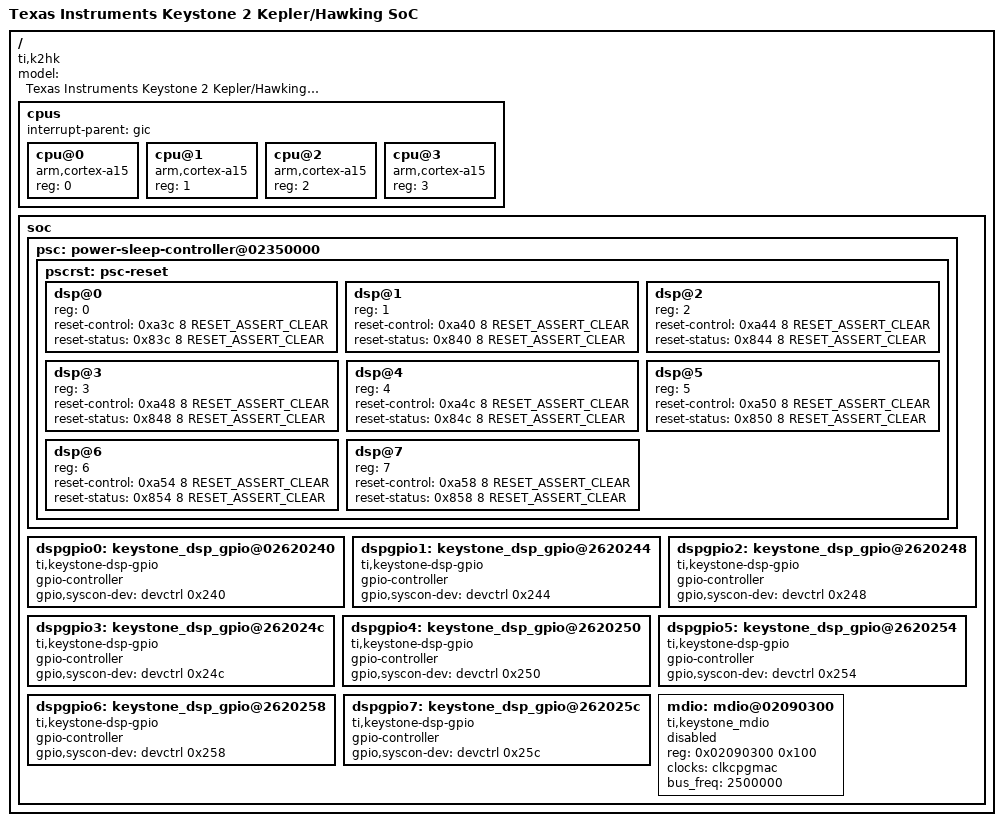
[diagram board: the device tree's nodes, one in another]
/*
 * Copyright 2013-2014 Texas Instruments, Inc.
 *
 * Keystone 2 Kepler/Hawking soc specific device tree
 *
 * This program is free software; you can redistribute it and/or modify
 * it under the terms of the GNU General Public License version 2 as
 * published by the Free Software Foundation.
 */

/ {
	compatible = "ti,k2hk", "ti,keystone";
	model = "Texas Instruments Keystone 2 Kepler/Hawking SoC";

	cpus {
		#address-cells = <1>;
		#size-cells = <0>;

		interrupt-parent = <&gic>;

		cpu@0 {
			compatible = "arm,cortex-a15";
			device_type = "cpu";
			reg = <0>;
		};

		cpu@1 {
			compatible = "arm,cortex-a15";
			device_type = "cpu";
			reg = <1>;
		};

		cpu@2 {
			compatible = "arm,cortex-a15";
			device_type = "cpu";
			reg = <2>;
		};

		cpu@3 {
			compatible = "arm,cortex-a15";
			device_type = "cpu";
			reg = <3>;
		};
	};

	soc {
		/include/ "keystone-k2hk-clocks.dtsi"

		psc: power-sleep-controller@02350000 {
			pscrst: psc-reset {
				dsp@0 {
					reg = <0>;
					reset-control = <0xa3c 8 RESET_ASSERT_CLEAR>;
					reset-status = <0x83c 8 RESET_ASSERT_CLEAR>;
				};

				dsp@1 {
					reg = <1>;
					reset-control = <0xa40 8 RESET_ASSERT_CLEAR>;
					reset-status = <0x840 8 RESET_ASSERT_CLEAR>;
				};

				dsp@2 {
					reg = <2>;
					reset-control = <0xa44 8 RESET_ASSERT_CLEAR>;
					reset-status = <0x844 8 RESET_ASSERT_CLEAR>;
				};

				dsp@3 {
					reg = <3>;
					reset-control = <0xa48 8 RESET_ASSERT_CLEAR>;
					reset-status = <0x848 8 RESET_ASSERT_CLEAR>;
				};

				dsp@4 {
					reg = <4>;
					reset-control = <0xa4c 8 RESET_ASSERT_CLEAR>;
					reset-status = <0x84c 8 RESET_ASSERT_CLEAR>;
				};

				dsp@5 {
					reg = <5>;
					reset-control = <0xa50 8 RESET_ASSERT_CLEAR>;
					reset-status = <0x850 8 RESET_ASSERT_CLEAR>;
				};

				dsp@6 {
					reg = <6>;
					reset-control = <0xa54 8 RESET_ASSERT_CLEAR>;
					reset-status = <0x854 8 RESET_ASSERT_CLEAR>;
				};

				dsp@7 {
					reg = <7>;
					reset-control = <0xa58 8 RESET_ASSERT_CLEAR>;
					reset-status = <0x858 8 RESET_ASSERT_CLEAR>;
				};
			};
		};

		dspgpio0: keystone_dsp_gpio@02620240 {
			compatible = "ti,keystone-dsp-gpio";
			gpio-controller;
			#gpio-cells = <2>;
			gpio,syscon-dev = <&devctrl 0x240>;
		};

		dspgpio1: keystone_dsp_gpio@2620244 {
			compatible = "ti,keystone-dsp-gpio";
			gpio-controller;
			#gpio-cells = <2>;
			gpio,syscon-dev = <&devctrl 0x244>;
		};

		dspgpio2: keystone_dsp_gpio@2620248 {
			compatible = "ti,keystone-dsp-gpio";
			gpio-controller;
			#gpio-cells = <2>;
			gpio,syscon-dev = <&devctrl 0x248>;
		};

		dspgpio3: keystone_dsp_gpio@262024c {
			compatible = "ti,keystone-dsp-gpio";
			gpio-controller;
			#gpio-cells = <2>;
			gpio,syscon-dev = <&devctrl 0x24c>;
		};

		dspgpio4: keystone_dsp_gpio@2620250 {
			compatible = "ti,keystone-dsp-gpio";
			gpio-controller;
			#gpio-cells = <2>;
			gpio,syscon-dev = <&devctrl 0x250>;
		};

		dspgpio5: keystone_dsp_gpio@2620254 {
			compatible = "ti,keystone-dsp-gpio";
			gpio-controller;
			#gpio-cells = <2>;
			gpio,syscon-dev = <&devctrl 0x254>;
		};

		dspgpio6: keystone_dsp_gpio@2620258 {
			compatible = "ti,keystone-dsp-gpio";
			gpio-controller;
			#gpio-cells = <2>;
			gpio,syscon-dev = <&devctrl 0x258>;
		};

		dspgpio7: keystone_dsp_gpio@262025c {
			compatible = "ti,keystone-dsp-gpio";
			gpio-controller;
			#gpio-cells = <2>;
			gpio,syscon-dev = <&devctrl 0x25c>;
		};

		mdio: mdio@02090300 {
			compatible	= "ti,keystone_mdio", "ti,davinci_mdio";
			#address-cells = <1>;
			#size-cells = <0>;
			reg = <0x02090300 0x100>;
			status = "disabled";
			clocks = <&clkcpgmac>;
			clock-names = "fck";
			bus_freq	= <2500000>;
		};
		/include/ "keystone-k2hk-netcp.dtsi"
	};
};
